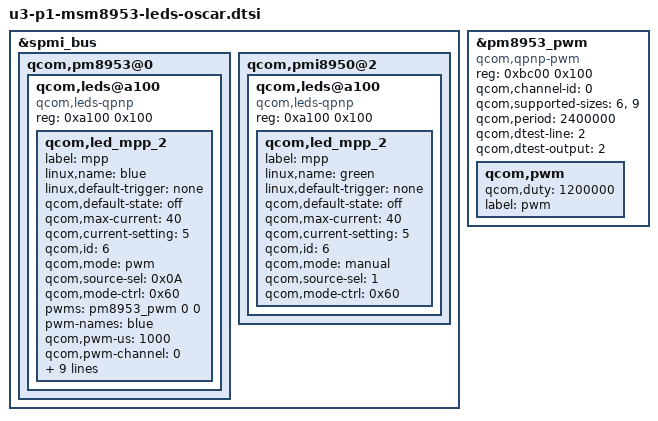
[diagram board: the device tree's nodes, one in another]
/* Copyright (c) 2014-2015, The Linux Foundation. All rights reserved.
 *
 * This program is free software; you can redistribute it and/or modify
 * it under the terms of the GNU General Public License version 2 and
 * only version 2 as published by the Free Software Foundation.
 *
 * This program is distributed in the hope that it will be useful,
 * but WITHOUT ANY WARRANTY; without even the implied warranty of
 * MERCHANTABILITY or FITNESS FOR A PARTICULAR PURPOSE.  See the
 * GNU General Public License for more details.
 */

&spmi_bus {
	qcom,pm8953@0 {
		qcom,leds@a100 {
			compatible = "qcom,leds-qpnp";
			reg = <0xa100 0x100>;
			status = "okay";
			qcom,led_mpp_2 {
				label = "mpp";
				linux,name = "blue";
				linux,default-trigger = "none";
				qcom,default-state = "off";
				qcom,max-current = <40>;
				qcom,current-setting = <5>;
				qcom,id = <6>;
				qcom,mode = "pwm";
				qcom,source-sel = <0x0A>;
				qcom,mode-ctrl = <0x60>;
				pwms = <&pm8953_pwm 0 0>;
				pwm-names = "blue";
				qcom,pwm-us = <1000>;
				qcom,pwm-channel = <0>;
				qcom,duty-pcts = [00 19 32 4b 64 64 4b 32 19 00];
				qcom,start-idx = <1>;
				qcom,idx-len = <10>;
				qcom,ramp-step-ms = <255>;
				qcom,pause-hi = <0>;
				qcom,pause-lo = <0>;
				qcom,lut-flags = <3>;
				qcom,use-blink;
			};
		};
	};

	qcom,pmi8950@2 {
		qcom,leds@a100 {
			compatible = "qcom,leds-qpnp";
			reg = <0xa100 0x100>;
			status = "okay";
			qcom,led_mpp_2 {
				label = "mpp";
				linux,name = "green";
				linux,default-trigger = "none";
				qcom,default-state = "off";
				qcom,max-current = <40>;
				qcom,current-setting = <5>;
				qcom,id = <6>;
				qcom,mode = "manual";
				qcom,source-sel = <1>;
				qcom,mode-ctrl = <0x60>;
			};
		};
	};
};

&pm8953_pwm {
	status = "okay";
	compatible = "qcom,qpnp-pwm";
	reg = <0xbc00 0x100>;
	reg-names = "qpnp-lpg-channel-base";
	qcom,channel-id = <0>;
	qcom,supported-sizes = <6>, <9>;
	qcom,period = <2400000>;
	#pwm-cells = <2>;
	qcom,dtest-line = <2>;
	qcom,dtest-output = <2>;
	qcom,pwm {
		qcom,duty = <1200000>;
		label = "pwm";
	};
};
